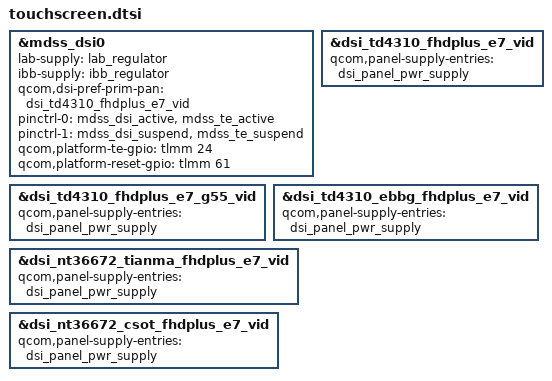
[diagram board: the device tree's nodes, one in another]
&mdss_dsi0 {
	lab-supply = <&lab_regulator>;
	ibb-supply = <&ibb_regulator>;
	/delete-property/ vdd-supply;
	qcom,dsi-pref-prim-pan = <&dsi_td4310_fhdplus_e7_vid>;
	pinctrl-names = "mdss_default", "mdss_sleep";
	pinctrl-0 = <&mdss_dsi_active &mdss_te_active>;
	pinctrl-1 = <&mdss_dsi_suspend &mdss_te_suspend>;
	qcom,platform-te-gpio = <&tlmm 24 0>;
	qcom,platform-reset-gpio = <&tlmm 61 0>;
};

&dsi_td4310_fhdplus_e7_vid {
	qcom,panel-supply-entries = <&dsi_panel_pwr_supply>;
};

&dsi_td4310_fhdplus_e7_g55_vid {
	qcom,panel-supply-entries = <&dsi_panel_pwr_supply>;
};


&dsi_td4310_ebbg_fhdplus_e7_vid {
	qcom,panel-supply-entries = <&dsi_panel_pwr_supply>;
};

&dsi_nt36672_tianma_fhdplus_e7_vid {
	qcom,panel-supply-entries = <&dsi_panel_pwr_supply>;
};

&dsi_nt36672_csot_fhdplus_e7_vid {
	qcom,panel-supply-entries = <&dsi_panel_pwr_supply>;
};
